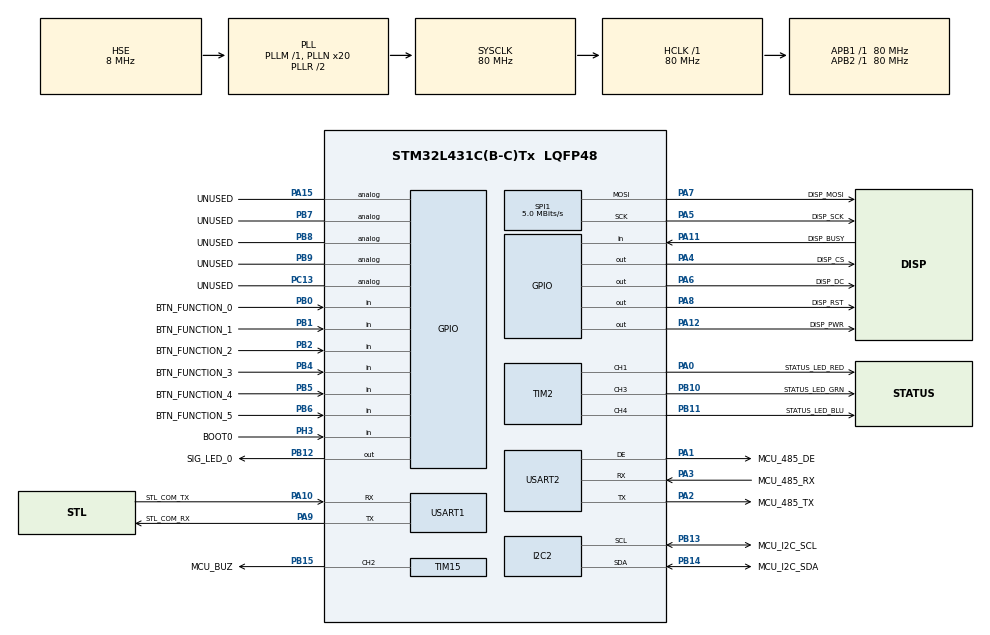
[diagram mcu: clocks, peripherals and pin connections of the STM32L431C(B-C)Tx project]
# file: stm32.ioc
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I2C2.Timing=0x10D19CE4
Mcu.Family=STM32L4
Mcu.Name=STM32L431C(B-C)Tx
Mcu.Package=LQFP48
NVIC.PriorityGroup=NVIC_PRIORITYGROUP_4
PA0.GPIO_Label=STATUS_LED_RED
PA0.Signal=S_TIM2_CH1
PA1.GPIO_Label=MCU_485_DE
PA1.Mode=Hardware Flow Control (RS485)
PA1.Signal=USART2_DE
PA10.GPIO_Label=STL_COM_TX
PA10.Mode=Asynchronous
PA10.Signal=USART1_RX
PA11.GPIO_Label=DISP_BUSY
PA11.Signal=GPIO_Input
PA12.GPIO_Label=DISP_PWR
PA12.Signal=GPIO_Output
PA13\ (JTMS-SWDIO).GPIO_Label=SWDIO
PA13\ (JTMS-SWDIO).Mode=Trace_Asynchronous_SW
PA13\ (JTMS-SWDIO).Signal=SYS_JTMS-SWDIO
PA14\ (JTCK-SWCLK).GPIO_Label=SWCLK
PA14\ (JTCK-SWCLK).Mode=Trace_Asynchronous_SW
PA14\ (JTCK-SWCLK).Signal=SYS_JTCK-SWCLK
PA15\ (JTDI).GPIO_Label=UNUSED
PA15\ (JTDI).Signal=GPIO_Analog
PA2.GPIO_Label=MCU_485_TX
PA2.Mode=Asynchronous
PA2.Signal=USART2_TX
PA3.GPIO_Label=MCU_485_RX
PA3.Mode=Asynchronous
PA3.Signal=USART2_RX
PA4.GPIO_Label=DISP_CS
PA4.Signal=GPIO_Output
PA5.GPIO_Label=DISP_SCK
PA5.Mode=TX_Only_Simplex_Unidirect_Master
PA5.Signal=SPI1_SCK
PA6.GPIO_Label=DISP_DC
PA6.Signal=GPIO_Output
PA7.GPIO_Label=DISP_MOSI
PA7.Mode=TX_Only_Simplex_Unidirect_Master
PA7.Signal=SPI1_MOSI
PA8.GPIO_Label=DISP_RST
PA8.Signal=GPIO_Output
PA9.GPIO_Label=STL_COM_RX
PA9.Mode=Asynchronous
PA9.Signal=USART1_TX
PB0.GPIO_Label=BTN_FUNCTION_0
PB0.Signal=GPIO_Input
PB1.GPIO_Label=BTN_FUNCTION_1
PB1.Signal=GPIO_Input
PB10.GPIO_Label=STATUS_LED_GRN
PB10.Signal=S_TIM2_CH3
PB11.GPIO_Label=STATUS_LED_BLU
PB11.Signal=S_TIM2_CH4
PB12.GPIO_Label=SIG_LED_0
PB12.Signal=GPIO_Output
PB13.GPIO_Label=MCU_I2C_SCL
PB13.Mode=I2C
PB13.Signal=I2C2_SCL
PB14.GPIO_Label=MCU_I2C_SDA
PB14.Mode=I2C
PB14.Signal=I2C2_SDA
PB15.GPIO_Label=MCU_BUZ
PB15.Signal=S_TIM15_CH2
PB2.GPIO_Label=BTN_FUNCTION_2
PB2.Signal=GPIO_Input
PB3\ (JTDO-TRACESWO).GPIO_Label=TRACESWO
PB3\ (JTDO-TRACESWO).Mode=Trace_Asynchronous_SW
PB3\ (JTDO-TRACESWO).Signal=SYS_JTDO-SWO
PB4\ (NJTRST).GPIO_Label=BTN_FUNCTION_3
PB4\ (NJTRST).Signal=GPIO_Input
PB5.GPIO_Label=BTN_FUNCTION_4
PB5.Signal=GPIO_Input
PB6.GPIO_Label=BTN_FUNCTION_5
PB6.Signal=GPIO_Input
PB7.GPIO_Label=UNUSED
PB7.Signal=GPIO_Analog
PB8.GPIO_Label=UNUSED
PB8.Signal=GPIO_Analog
PB9.GPIO_Label=UNUSED
PB9.Signal=GPIO_Analog
PC13.GPIO_Label=UNUSED
PC13.Signal=GPIO_Analog
PC14-OSC32_IN\ (PC14).Mode=LSE-External-Oscillator
PC14-OSC32_IN\ (PC14).Signal=RCC_OSC32_IN
PC15-OSC32_OUT\ (PC15).Mode=LSE-External-Oscillator
PC15-OSC32_OUT\ (PC15).Signal=RCC_OSC32_OUT
PH0-OSC_IN\ (PH0).Mode=HSE-External-Oscillator
PH0-OSC_IN\ (PH0).Signal=RCC_OSC_IN
PH1-OSC_OUT\ (PH1).Mode=HSE-External-Oscillator
PH1-OSC_OUT\ (PH1).Signal=RCC_OSC_OUT
PH3-BOOT0.GPIO_Label=BOOT0
PH3-BOOT0.Signal=GPIO_Input
ProjectManager.HeapSize=0x200
ProjectManager.StackSize=0x400
ProjectManager.TargetToolchain=CMake
RCC.ADCFreq_Value=32000000
RCC.AHBFreq_Value=80000000
RCC.APB1Freq_Value=80000000
RCC.APB1TimFreq_Value=80000000
RCC.APB2Freq_Value=80000000
RCC.APB2TimFreq_Value=80000000
RCC.CortexFreq_Value=80000000
RCC.HCLKFreq_Value=80000000
RCC.HSE_VALUE=8000000
RCC.HSI48_VALUE=48000000
RCC.HSI_VALUE=16000000
RCC.MSI_VALUE=4000000
RCC.PLLN=20
RCC.PLLSourceVirtual=RCC_PLLSOURCE_HSE
RCC.RTCClockSelection=RCC_RTCCLKSOURCE_LSE
RCC.SYSCLKFreq_VALUE=80000000
RCC.SYSCLKSource=RCC_SYSCLKSOURCE_PLLCLK
RCC.VCOOutputFreq_Value=160000000
SH.S_TIM15_CH2.0=TIM15_CH2,PWM Generation2 CH2
SH.S_TIM2_CH1.0=TIM2_CH1,PWM Generation1 CH1
SH.S_TIM2_CH3.0=TIM2_CH3,PWM Generation3 CH3
SH.S_TIM2_CH4.0=TIM2_CH4,PWM Generation4 CH4
SPI1.BaudRatePrescaler=SPI_BAUDRATEPRESCALER_16
SPI1.CalculateBaudRate=5.0 MBits/s
SPI1.DataSize=SPI_DATASIZE_8BIT
SPI1.Direction=SPI_DIRECTION_2LINES
SPI1.Mode=SPI_MODE_MASTER
SPI1.VirtualType=VM_MASTER
TIM15.Channel-PWM\ Generation2\ CH2=TIM_CHANNEL_2
TIM2.Channel-PWM\ Generation1\ CH1=TIM_CHANNEL_1
TIM2.Channel-PWM\ Generation3\ CH3=TIM_CHANNEL_3
TIM2.Channel-PWM\ Generation4\ CH4=TIM_CHANNEL_4
USART1.VirtualMode-Asynchronous=VM_ASYNC
USART2.VirtualMode-Asynchronous=VM_ASYNC
USART2.VirtualMode-Hardware\ Flow\ Control\ (RS485)=VM_ASYNC
VP_RTC_VS_RTC_Activate.Mode=RTC_Enabled
board=custom

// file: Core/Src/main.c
/* USER CODE BEGIN Header */
/**
  ******************************************************************************
  * @file           : main.c
  * @brief          : Main program body
  ******************************************************************************
  * @attention
  *
  * Copyright (c) 2026 STMicroelectronics.
  * All rights reserved.
  *
  * This software is licensed under terms that can be found in the LICENSE file
  * in the root directory of this software component.
  * If no LICENSE file comes with this software, it is provided AS-IS.
  *
  ******************************************************************************
  */
/* USER CODE END Header */
#include "main.h"

/* USER CODE BEGIN Includes */
#include "remote_a/app.h"
/* USER CODE END Includes */

I2C_HandleTypeDef hi2c2;

RTC_HandleTypeDef hrtc;

SPI_HandleTypeDef hspi1;

TIM_HandleTypeDef htim2;
TIM_HandleTypeDef htim15;

UART_HandleTypeDef huart1;
UART_HandleTypeDef huart2;

void SystemClock_Config(void);
static void MX_GPIO_Init(void);
static void MX_I2C2_Init(void);
static void MX_TIM2_Init(void);
static void MX_USART1_UART_Init(void);
static void MX_USART2_UART_Init(void);
static void MX_SPI1_Init(void);
static void MX_TIM15_Init(void);
static void MX_RTC_Init(void);

int main(void)
{

  /* MCU Configuration--------------------------------------------------------*/

  /* Reset of all peripherals, Initializes the Flash interface and the Systick. */
  HAL_Init();

  /* Configure the system clock */
  SystemClock_Config();

  /* Initialize all configured peripherals */
  MX_GPIO_Init();
  MX_I2C2_Init();
  MX_TIM2_Init();
  MX_USART1_UART_Init();
  MX_USART2_UART_Init();
  MX_SPI1_Init();
  MX_TIM15_Init();
  MX_RTC_Init();
  /* USER CODE BEGIN 2 */
  remote_a_app_init();
  /* USER CODE END 2 */

  /* Infinite loop */
  while (1)
  {

    /* USER CODE BEGIN 3 */
    remote_a_app_run();
  }
  /* USER CODE END 3 */
}

void SystemClock_Config(void)
{
  RCC_OscInitTypeDef RCC_OscInitStruct = {0};
  RCC_ClkInitTypeDef RCC_ClkInitStruct = {0};

  /** Configure the main internal regulator output voltage
  */
  if (HAL_PWREx_ControlVoltageScaling(PWR_REGULATOR_VOLTAGE_SCALE1) != HAL_OK)
  {
    Error_Handler();
  }

  /** Configure LSE Drive Capability
  */
  HAL_PWR_EnableBkUpAccess();
  __HAL_RCC_LSEDRIVE_CONFIG(RCC_LSEDRIVE_LOW);

  /** Initializes the RCC Oscillators according to the specified parameters
  * in the RCC_OscInitTypeDef structure.
  */
  RCC_OscInitStruct.OscillatorType = RCC_OSCILLATORTYPE_HSE|RCC_OSCILLATORTYPE_LSE;
  RCC_OscInitStruct.HSEState = RCC_HSE_ON;
  RCC_OscInitStruct.LSEState = RCC_LSE_ON;
  RCC_OscInitStruct.PLL.PLLState = RCC_PLL_ON;
  RCC_OscInitStruct.PLL.PLLSource = RCC_PLLSOURCE_HSE;
  RCC_OscInitStruct.PLL.PLLM = 1;
  RCC_OscInitStruct.PLL.PLLN = 20;
  RCC_OscInitStruct.PLL.PLLP = RCC_PLLP_DIV7;
  RCC_OscInitStruct.PLL.PLLQ = RCC_PLLQ_DIV2;
  RCC_OscInitStruct.PLL.PLLR = RCC_PLLR_DIV2;
  if (HAL_RCC_OscConfig(&RCC_OscInitStruct) != HAL_OK)
  {
    Error_Handler();
  }

  /** Initializes the CPU, AHB and APB buses clocks
  */
  RCC_ClkInitStruct.ClockType = RCC_CLOCKTYPE_HCLK|RCC_CLOCKTYPE_SYSCLK
                              |RCC_CLOCKTYPE_PCLK1|RCC_CLOCKTYPE_PCLK2;
  RCC_ClkInitStruct.SYSCLKSource = RCC_SYSCLKSOURCE_PLLCLK;
  RCC_ClkInitStruct.AHBCLKDivider = RCC_SYSCLK_DIV1;
  RCC_ClkInitStruct.APB1CLKDivider = RCC_HCLK_DIV1;
  RCC_ClkInitStruct.APB2CLKDivider = RCC_HCLK_DIV1;

  if (HAL_RCC_ClockConfig(&RCC_ClkInitStruct, FLASH_LATENCY_4) != HAL_OK)
  {
    Error_Handler();
  }
}

static void MX_I2C2_Init(void)
{

  hi2c2.Instance = I2C2;
  hi2c2.Init.Timing = 0x10D19CE4;
  hi2c2.Init.OwnAddress1 = 0;
  hi2c2.Init.AddressingMode = I2C_ADDRESSINGMODE_7BIT;
  hi2c2.Init.DualAddressMode = I2C_DUALADDRESS_DISABLE;
  hi2c2.Init.OwnAddress2 = 0;
  hi2c2.Init.OwnAddress2Masks = I2C_OA2_NOMASK;
  hi2c2.Init.GeneralCallMode = I2C_GENERALCALL_DISABLE;
  hi2c2.Init.NoStretchMode = I2C_NOSTRETCH_DISABLE;
  if (HAL_I2C_Init(&hi2c2) != HAL_OK)
  {
    Error_Handler();
  }

  /** Configure Analogue filter
  */
  if (HAL_I2CEx_ConfigAnalogFilter(&hi2c2, I2C_ANALOGFILTER_ENABLE) != HAL_OK)
  {
    Error_Handler();
  }

  /** Configure Digital filter
  */
  if (HAL_I2CEx_ConfigDigitalFilter(&hi2c2, 0) != HAL_OK)
  {
    Error_Handler();
  }

}

static void MX_RTC_Init(void)
{

  /** Initialize RTC Only
  */
  hrtc.Instance = RTC;
  hrtc.Init.HourFormat = RTC_HOURFORMAT_24;
  hrtc.Init.AsynchPrediv = 127;
  hrtc.Init.SynchPrediv = 255;
  hrtc.Init.OutPut = RTC_OUTPUT_DISABLE;
  hrtc.Init.OutPutRemap = RTC_OUTPUT_REMAP_NONE;
  hrtc.Init.OutPutPolarity = RTC_OUTPUT_POLARITY_HIGH;
  hrtc.Init.OutPutType = RTC_OUTPUT_TYPE_OPENDRAIN;
  if (HAL_RTC_Init(&hrtc) != HAL_OK)
  {
    Error_Handler();
  }

}

static void MX_SPI1_Init(void)
{

  /* SPI1 parameter configuration*/
  hspi1.Instance = SPI1;
  hspi1.Init.Mode = SPI_MODE_MASTER;
  hspi1.Init.Direction = SPI_DIRECTION_2LINES;
  hspi1.Init.DataSize = SPI_DATASIZE_8BIT;
  hspi1.Init.CLKPolarity = SPI_POLARITY_LOW;
  hspi1.Init.CLKPhase = SPI_PHASE_1EDGE;
  hspi1.Init.NSS = SPI_NSS_SOFT;
  hspi1.Init.BaudRatePrescaler = SPI_BAUDRATEPRESCALER_16;
  hspi1.Init.FirstBit = SPI_FIRSTBIT_MSB;
  hspi1.Init.TIMode = SPI_TIMODE_DISABLE;
  hspi1.Init.CRCCalculation = SPI_CRCCALCULATION_DISABLE;
  hspi1.Init.CRCPolynomial = 7;
  hspi1.Init.CRCLength = SPI_CRC_LENGTH_DATASIZE;
  hspi1.Init.NSSPMode = SPI_NSS_PULSE_ENABLE;
  if (HAL_SPI_Init(&hspi1) != HAL_OK)
  {
    Error_Handler();
  }

}

static void MX_TIM2_Init(void)
{

  TIM_MasterConfigTypeDef sMasterConfig = {0};
  TIM_OC_InitTypeDef sConfigOC = {0};

  htim2.Instance = TIM2;
  htim2.Init.Prescaler = 0;
  htim2.Init.CounterMode = TIM_COUNTERMODE_UP;
  htim2.Init.Period = 4294967295;
  htim2.Init.ClockDivision = TIM_CLOCKDIVISION_DIV1;
  htim2.Init.AutoReloadPreload = TIM_AUTORELOAD_PRELOAD_DISABLE;
  if (HAL_TIM_PWM_Init(&htim2) != HAL_OK)
  {
    Error_Handler();
  }
  sMasterConfig.MasterOutputTrigger = TIM_TRGO_RESET;
  sMasterConfig.MasterSlaveMode = TIM_MASTERSLAVEMODE_DISABLE;
  if (HAL_TIMEx_MasterConfigSynchronization(&htim2, &sMasterConfig) != HAL_OK)
  {
    Error_Handler();
  }
  sConfigOC.OCMode = TIM_OCMODE_PWM1;
  sConfigOC.Pulse = 0;
  sConfigOC.OCPolarity = TIM_OCPOLARITY_HIGH;
  sConfigOC.OCFastMode = TIM_OCFAST_DISABLE;
  if (HAL_TIM_PWM_ConfigChannel(&htim2, &sConfigOC, TIM_CHANNEL_1) != HAL_OK)
  {
    Error_Handler();
  }
  if (HAL_TIM_PWM_ConfigChannel(&htim2, &sConfigOC, TIM_CHANNEL_3) != HAL_OK)
  {
    Error_Handler();
  }
  if (HAL_TIM_PWM_ConfigChannel(&htim2, &sConfigOC, TIM_CHANNEL_4) != HAL_OK)
  {
    Error_Handler();
  }
  HAL_TIM_MspPostInit(&htim2);

}

static void MX_TIM15_Init(void)
{

  TIM_MasterConfigTypeDef sMasterConfig = {0};
  TIM_OC_InitTypeDef sConfigOC = {0};
  TIM_BreakDeadTimeConfigTypeDef sBreakDeadTimeConfig = {0};

  htim15.Instance = TIM15;
  htim15.Init.Prescaler = 0;
  htim15.Init.CounterMode = TIM_COUNTERMODE_UP;
  htim15.Init.Period = 65535;
  htim15.Init.ClockDivision = TIM_CLOCKDIVISION_DIV1;
  htim15.Init.RepetitionCounter = 0;
  htim15.Init.AutoReloadPreload = TIM_AUTORELOAD_PRELOAD_DISABLE;
  if (HAL_TIM_PWM_Init(&htim15) != HAL_OK)
  {
    Error_Handler();
  }
  sMasterConfig.MasterOutputTrigger = TIM_TRGO_RESET;
  sMasterConfig.MasterSlaveMode = TIM_MASTERSLAVEMODE_DISABLE;
  if (HAL_TIMEx_MasterConfigSynchronization(&htim15, &sMasterConfig) != HAL_OK)
  {
    Error_Handler();
  }
  sConfigOC.OCMode = TIM_OCMODE_PWM1;
  sConfigOC.Pulse = 0;
  sConfigOC.OCPolarity = TIM_OCPOLARITY_HIGH;
  sConfigOC.OCNPolarity = TIM_OCNPOLARITY_HIGH;
  sConfigOC.OCFastMode = TIM_OCFAST_DISABLE;
  sConfigOC.OCIdleState = TIM_OCIDLESTATE_RESET;
  sConfigOC.OCNIdleState = TIM_OCNIDLESTATE_RESET;
  if (HAL_TIM_PWM_ConfigChannel(&htim15, &sConfigOC, TIM_CHANNEL_2) != HAL_OK)
  {
    Error_Handler();
  }
  sBreakDeadTimeConfig.OffStateRunMode = TIM_OSSR_DISABLE;
  sBreakDeadTimeConfig.OffStateIDLEMode = TIM_OSSI_DISABLE;
  sBreakDeadTimeConfig.LockLevel = TIM_LOCKLEVEL_OFF;
  sBreakDeadTimeConfig.DeadTime = 0;
  sBreakDeadTimeConfig.BreakState = TIM_BREAK_DISABLE;
  sBreakDeadTimeConfig.BreakPolarity = TIM_BREAKPOLARITY_HIGH;
  sBreakDeadTimeConfig.AutomaticOutput = TIM_AUTOMATICOUTPUT_DISABLE;
  if (HAL_TIMEx_ConfigBreakDeadTime(&htim15, &sBreakDeadTimeConfig) != HAL_OK)
  {
    Error_Handler();
  }
  HAL_TIM_MspPostInit(&htim15);

}

static void MX_USART1_UART_Init(void)
{

  huart1.Instance = USART1;
  huart1.Init.BaudRate = 115200;
  huart1.Init.WordLength = UART_WORDLENGTH_8B;
  huart1.Init.StopBits = UART_STOPBITS_1;
  huart1.Init.Parity = UART_PARITY_NONE;
  huart1.Init.Mode = UART_MODE_TX_RX;
  huart1.Init.HwFlowCtl = UART_HWCONTROL_NONE;
  huart1.Init.OverSampling = UART_OVERSAMPLING_16;
  huart1.Init.OneBitSampling = UART_ONE_BIT_SAMPLE_DISABLE;
  huart1.AdvancedInit.AdvFeatureInit = UART_ADVFEATURE_NO_INIT;
  if (HAL_UART_Init(&huart1) != HAL_OK)
  {
    Error_Handler();
  }

}

static void MX_USART2_UART_Init(void)
{

  huart2.Instance = USART2;
  huart2.Init.BaudRate = 115200;
  huart2.Init.WordLength = UART_WORDLENGTH_8B;
  huart2.Init.StopBits = UART_STOPBITS_1;
  huart2.Init.Parity = UART_PARITY_NONE;
  huart2.Init.Mode = UART_MODE_TX_RX;
  huart2.Init.HwFlowCtl = UART_HWCONTROL_NONE;
  huart2.Init.OverSampling = UART_OVERSAMPLING_16;
  huart2.Init.OneBitSampling = UART_ONE_BIT_SAMPLE_DISABLE;
  huart2.AdvancedInit.AdvFeatureInit = UART_ADVFEATURE_NO_INIT;
  if (HAL_RS485Ex_Init(&huart2, UART_DE_POLARITY_HIGH, 0, 0) != HAL_OK)
  {
    Error_Handler();
  }

}

static void MX_GPIO_Init(void)
{
  GPIO_InitTypeDef GPIO_InitStruct = {0};

  /* GPIO Ports Clock Enable */
  __HAL_RCC_GPIOC_CLK_ENABLE();
  __HAL_RCC_GPIOH_CLK_ENABLE();
  __HAL_RCC_GPIOA_CLK_ENABLE();
  __HAL_RCC_GPIOB_CLK_ENABLE();

  /*Configure GPIO pin Output Level */
  HAL_GPIO_WritePin(GPIOA, DISP_CS_Pin|DISP_DC_Pin|DISP_RST_Pin|DISP_PWR_Pin, GPIO_PIN_RESET);

  /*Configure GPIO pin Output Level */
  HAL_GPIO_WritePin(SIG_LED_0_GPIO_Port, SIG_LED_0_Pin, GPIO_PIN_RESET);

  /*Configure GPIO pin : UNUSED_Pin */
  GPIO_InitStruct.Pin = UNUSED_Pin;
  GPIO_InitStruct.Mode = GPIO_MODE_ANALOG;
  GPIO_InitStruct.Pull = GPIO_NOPULL;
  HAL_GPIO_Init(UNUSED_GPIO_Port, &GPIO_InitStruct);

  /*Configure GPIO pins : DISP_CS_Pin DISP_DC_Pin DISP_RST_Pin DISP_PWR_Pin */
  GPIO_InitStruct.Pin = DISP_CS_Pin|DISP_DC_Pin|DISP_RST_Pin|DISP_PWR_Pin;
  GPIO_InitStruct.Mode = GPIO_MODE_OUTPUT_PP;
  GPIO_InitStruct.Pull = GPIO_NOPULL;
  GPIO_InitStruct.Speed = GPIO_SPEED_FREQ_LOW;
  HAL_GPIO_Init(GPIOA, &GPIO_InitStruct);

  /*Configure GPIO pins : BTN_FUNCTION_0_Pin BTN_FUNCTION_1_Pin BTN_FUNCTION_2_Pin BTN_FUNCTION_3_Pin
                           BTN_FUNCTION_4_Pin BTN_FUNCTION_5_Pin */
  GPIO_InitStruct.Pin = BTN_FUNCTION_0_Pin|BTN_FUNCTION_1_Pin|BTN_FUNCTION_2_Pin|BTN_FUNCTION_3_Pin
                          |BTN_FUNCTION_4_Pin|BTN_FUNCTION_5_Pin;
  GPIO_InitStruct.Mode = GPIO_MODE_INPUT;
  GPIO_InitStruct.Pull = GPIO_NOPULL;
  HAL_GPIO_Init(GPIOB, &GPIO_InitStruct);

  /*Configure GPIO pin : SIG_LED_0_Pin */
  GPIO_InitStruct.Pin = SIG_LED_0_Pin;
  GPIO_InitStruct.Mode = GPIO_MODE_OUTPUT_PP;
  GPIO_InitStruct.Pull = GPIO_NOPULL;
  GPIO_InitStruct.Speed = GPIO_SPEED_FREQ_LOW;
  HAL_GPIO_Init(SIG_LED_0_GPIO_Port, &GPIO_InitStruct);

  /*Configure GPIO pin : DISP_BUSY_Pin */
  GPIO_InitStruct.Pin = DISP_BUSY_Pin;
  GPIO_InitStruct.Mode = GPIO_MODE_INPUT;
  GPIO_InitStruct.Pull = GPIO_NOPULL;
  HAL_GPIO_Init(DISP_BUSY_GPIO_Port, &GPIO_InitStruct);

  /*Configure GPIO pin : UNUSEDA15_Pin */
  GPIO_InitStruct.Pin = UNUSEDA15_Pin;
  GPIO_InitStruct.Mode = GPIO_MODE_ANALOG;
  GPIO_InitStruct.Pull = GPIO_NOPULL;
  HAL_GPIO_Init(UNUSEDA15_GPIO_Port, &GPIO_InitStruct);

  /*Configure GPIO pins : UNUSEDB7_Pin UNUSEDB8_Pin UNUSEDB9_Pin */
  GPIO_InitStruct.Pin = UNUSEDB7_Pin|UNUSEDB8_Pin|UNUSEDB9_Pin;
  GPIO_InitStruct.Mode = GPIO_MODE_ANALOG;
  GPIO_InitStruct.Pull = GPIO_NOPULL;
  HAL_GPIO_Init(GPIOB, &GPIO_InitStruct);

  /*Configure GPIO pin : BOOT0_Pin */
  GPIO_InitStruct.Pin = BOOT0_Pin;
  GPIO_InitStruct.Mode = GPIO_MODE_INPUT;
  GPIO_InitStruct.Pull = GPIO_NOPULL;
  HAL_GPIO_Init(BOOT0_GPIO_Port, &GPIO_InitStruct);

}

void Error_Handler(void)
{
  __disable_irq();
  while (1)
  {
  }
}
